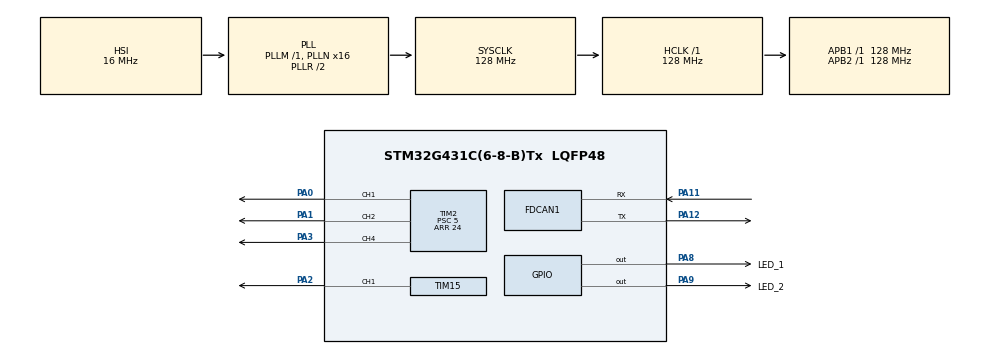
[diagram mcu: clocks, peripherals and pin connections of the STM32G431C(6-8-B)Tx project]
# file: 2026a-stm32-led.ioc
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Dma.Request0=TIM15_CH1
Dma.Request1=TIM2_CH4
Dma.Request2=TIM2_CH1
Dma.Request3=TIM2_CH2
Dma.TIM15_CH1.0.Direction=DMA_MEMORY_TO_PERIPH
Dma.TIM15_CH1.0.EventEnable=DISABLE
Dma.TIM15_CH1.0.Instance=DMA1_Channel1
Dma.TIM15_CH1.0.MemDataAlignment=DMA_MDATAALIGN_HALFWORD
Dma.TIM15_CH1.0.MemInc=DMA_MINC_ENABLE
Dma.TIM15_CH1.0.Mode=DMA_CIRCULAR
Dma.TIM15_CH1.0.PeriphDataAlignment=DMA_PDATAALIGN_HALFWORD
Dma.TIM15_CH1.0.PeriphInc=DMA_PINC_DISABLE
Dma.TIM15_CH1.0.Polarity=HAL_DMAMUX_REQ_GEN_RISING
Dma.TIM15_CH1.0.Priority=DMA_PRIORITY_MEDIUM
Dma.TIM15_CH1.0.RequestNumber=1
Dma.TIM15_CH1.0.SignalID=NONE
Dma.TIM15_CH1.0.SyncEnable=DISABLE
Dma.TIM15_CH1.0.SyncPolarity=HAL_DMAMUX_SYNC_NO_EVENT
Dma.TIM15_CH1.0.SyncRequestNumber=1
Dma.TIM15_CH1.0.SyncSignalID=NONE
Dma.TIM2_CH1.2.Direction=DMA_MEMORY_TO_PERIPH
Dma.TIM2_CH1.2.EventEnable=DISABLE
Dma.TIM2_CH1.2.Instance=DMA1_Channel3
Dma.TIM2_CH1.2.MemDataAlignment=DMA_MDATAALIGN_WORD
Dma.TIM2_CH1.2.MemInc=DMA_MINC_ENABLE
Dma.TIM2_CH1.2.Mode=DMA_CIRCULAR
Dma.TIM2_CH1.2.PeriphDataAlignment=DMA_PDATAALIGN_WORD
Dma.TIM2_CH1.2.PeriphInc=DMA_PINC_DISABLE
Dma.TIM2_CH1.2.Polarity=HAL_DMAMUX_REQ_GEN_RISING
Dma.TIM2_CH1.2.Priority=DMA_PRIORITY_LOW
Dma.TIM2_CH1.2.RequestNumber=1
Dma.TIM2_CH1.2.SignalID=NONE
Dma.TIM2_CH1.2.SyncEnable=DISABLE
Dma.TIM2_CH1.2.SyncPolarity=HAL_DMAMUX_SYNC_NO_EVENT
Dma.TIM2_CH1.2.SyncRequestNumber=1
Dma.TIM2_CH1.2.SyncSignalID=NONE
Dma.TIM2_CH2.3.Direction=DMA_MEMORY_TO_PERIPH
Dma.TIM2_CH2.3.EventEnable=DISABLE
Dma.TIM2_CH2.3.Instance=DMA1_Channel4
Dma.TIM2_CH2.3.MemDataAlignment=DMA_MDATAALIGN_WORD
Dma.TIM2_CH2.3.MemInc=DMA_MINC_ENABLE
Dma.TIM2_CH2.3.Mode=DMA_CIRCULAR
Dma.TIM2_CH2.3.PeriphDataAlignment=DMA_PDATAALIGN_WORD
Dma.TIM2_CH2.3.PeriphInc=DMA_PINC_DISABLE
Dma.TIM2_CH2.3.Polarity=HAL_DMAMUX_REQ_GEN_RISING
Dma.TIM2_CH2.3.Priority=DMA_PRIORITY_LOW
Dma.TIM2_CH2.3.RequestNumber=1
Dma.TIM2_CH2.3.SignalID=NONE
Dma.TIM2_CH2.3.SyncEnable=DISABLE
Dma.TIM2_CH2.3.SyncPolarity=HAL_DMAMUX_SYNC_NO_EVENT
Dma.TIM2_CH2.3.SyncRequestNumber=1
Dma.TIM2_CH2.3.SyncSignalID=NONE
Dma.TIM2_CH4.1.Direction=DMA_MEMORY_TO_PERIPH
Dma.TIM2_CH4.1.EventEnable=DISABLE
Dma.TIM2_CH4.1.Instance=DMA1_Channel2
Dma.TIM2_CH4.1.MemDataAlignment=DMA_MDATAALIGN_WORD
Dma.TIM2_CH4.1.MemInc=DMA_MINC_ENABLE
Dma.TIM2_CH4.1.Mode=DMA_CIRCULAR
Dma.TIM2_CH4.1.PeriphDataAlignment=DMA_PDATAALIGN_WORD
Dma.TIM2_CH4.1.PeriphInc=DMA_PINC_DISABLE
Dma.TIM2_CH4.1.Polarity=HAL_DMAMUX_REQ_GEN_RISING
Dma.TIM2_CH4.1.Priority=DMA_PRIORITY_LOW
Dma.TIM2_CH4.1.RequestNumber=1
Dma.TIM2_CH4.1.SignalID=NONE
Dma.TIM2_CH4.1.SyncEnable=DISABLE
Dma.TIM2_CH4.1.SyncPolarity=HAL_DMAMUX_SYNC_NO_EVENT
Dma.TIM2_CH4.1.SyncRequestNumber=1
Dma.TIM2_CH4.1.SyncSignalID=NONE
FDCAN1.CalculateBaudRateNominal=1000000
FDCAN1.CalculateTimeBitNominal=1000
FDCAN1.CalculateTimeQuantumNominal=62.5
FDCAN1.FrameFormat=FDCAN_FRAME_FD_NO_BRS
FDCAN1.NominalPrescaler=8
FDCAN1.NominalSyncJumpWidth=2
FDCAN1.NominalTimeSeg1=13
FDCAN1.NominalTimeSeg2=2
Mcu.Family=STM32G4
Mcu.Name=STM32G431C(6-8-B)Tx
Mcu.Package=LQFP48
NVIC.DMA1_Channel1_IRQn=true\:4\:0\:true\:false\:true\:false\:true\:true
NVIC.DMA1_Channel2_IRQn=true\:4\:0\:true\:false\:true\:false\:true\:true
NVIC.DMA1_Channel3_IRQn=true\:4\:0\:true\:false\:true\:false\:true\:true
NVIC.DMA1_Channel4_IRQn=true\:4\:0\:true\:false\:true\:false\:true\:true
NVIC.FDCAN1_IT0_IRQn=true\:7\:0\:true\:false\:true\:true\:true\:true
NVIC.PriorityGroup=NVIC_PRIORITYGROUP_4
NVIC.TIM1_BRK_TIM15_IRQn=true\:5\:0\:true\:false\:true\:true\:true\:true
NVIC.TIM2_IRQn=true\:6\:0\:true\:false\:true\:true\:true\:true
NVIC.TIM7_IRQn=true\:7\:0\:true\:false\:true\:true\:true\:true
PA0.Signal=S_TIM2_CH1
PA1.Signal=S_TIM2_CH2
PA11.Mode=FDCAN_Activate
PA11.Signal=FDCAN1_RX
PA12.Mode=FDCAN_Activate
PA12.Signal=FDCAN1_TX
PA13.Mode=Serial_Wire
PA13.Signal=SYS_JTMS-SWDIO
PA14.Mode=Serial_Wire
PA14.Signal=SYS_JTCK-SWCLK
PA2.Signal=S_TIM15_CH1
PA3.Signal=S_TIM2_CH4
PA8.GPIO_Label=LED_1
PA8.Signal=GPIO_Output
PA9.GPIO_Label=LED_2
PA9.Signal=GPIO_Output
ProjectManager.HeapSize=0x200
ProjectManager.StackSize=0x400
ProjectManager.TargetToolchain=CMake
RCC.ADC12Freq_Value=128000000
RCC.AHBFreq_Value=128000000
RCC.APB1Freq_Value=128000000
RCC.APB1TimFreq_Value=128000000
RCC.APB2Freq_Value=128000000
RCC.APB2TimFreq_Value=128000000
RCC.CortexFreq_Value=128000000
RCC.EXTERNAL_CLOCK_VALUE=12288000
RCC.HCLKFreq_Value=128000000
RCC.HSE_VALUE=8000000
RCC.HSI48_VALUE=48000000
RCC.HSI_VALUE=16000000
RCC.LSE_VALUE=32768
RCC.PLLN=16
RCC.SYSCLKFreq_VALUE=128000000
RCC.SYSCLKSource=RCC_SYSCLKSOURCE_PLLCLK
RCC.USBFreq_Value=128000000
RCC.VCOOutputFreq_Value=256000000
SH.S_TIM15_CH1.0=TIM15_CH1,PWM Generation1 CH1
SH.S_TIM2_CH1.0=TIM2_CH1,PWM Generation1 CH1
SH.S_TIM2_CH2.0=TIM2_CH2,PWM Generation2 CH2
SH.S_TIM2_CH4.0=TIM2_CH4,PWM Generation4 CH4
TIM15.AutoReloadPreload=TIM_AUTORELOAD_PRELOAD_ENABLE
TIM15.Channel-PWM\ Generation1\ CH1=TIM_CHANNEL_1
TIM15.OCIdleState_1=TIM_OCIDLESTATE_RESET
TIM15.PeriodNoDither=24
TIM15.Prescaler=5
TIM15.TIM_MasterOutputTrigger=TIM_TRGO_RESET
TIM2.AutoReloadPreload=TIM_AUTORELOAD_PRELOAD_ENABLE
TIM2.Channel-PWM\ Generation1\ CH1=TIM_CHANNEL_1
TIM2.Channel-PWM\ Generation2\ CH2=TIM_CHANNEL_2
TIM2.Channel-PWM\ Generation4\ CH4=TIM_CHANNEL_4
TIM2.PeriodNoDither=24
TIM2.Prescaler=5
TIM7.PeriodNoDither=9999
TIM7.Prescaler=127
VP_SYS_VS_DBSignals.Mode=DisableDeadBatterySignals
VP_TIM15_VS_ClockSourceINT.Mode=Internal
VP_TIM2_VS_ClockSourceINT.Mode=Internal
VP_TIM7_VS_ClockSourceINT.Mode=Enable_Timer
board=custom

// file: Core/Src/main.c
/* USER CODE BEGIN Header */
/**
 ******************************************************************************
 * @file           : main.c
 * @brief          : Main program body
 ******************************************************************************
 * @attention
 *
 * Copyright (c) 2026 STMicroelectronics.
 * All rights reserved.
 *
 * This software is licensed under terms that can be found in the LICENSE file
 * in the root directory of this software component.
 * If no LICENSE file comes with this software, it is provided AS-IS.
 *
 ******************************************************************************
 */
/* USER CODE END Header */
#include "main.h"
#include "dma.h"
#include "fdcan.h"
#include "tim.h"
#include "gpio.h"

/* USER CODE BEGIN Includes */
#include "app/app.hpp"
/* USER CODE END Includes */

void SystemClock_Config(void);

int main(void)
{

  /* MCU Configuration--------------------------------------------------------*/

  /* Reset of all peripherals, Initializes the Flash interface and the Systick. */
  HAL_Init();

  /* Configure the system clock */
  SystemClock_Config();

  /* Initialize all configured peripherals */
  MX_GPIO_Init();
  MX_DMA_Init();
  MX_FDCAN1_Init();
  MX_TIM2_Init();
  MX_TIM15_Init();
  MX_TIM7_Init();
  /* USER CODE BEGIN 2 */
    setup();
  /* USER CODE END 2 */

  /* Infinite loop */
    while (1) {

    /* USER CODE BEGIN 3 */
        loop();
    }
  /* USER CODE END 3 */
}

void SystemClock_Config(void)
{
  RCC_OscInitTypeDef RCC_OscInitStruct = {0};
  RCC_ClkInitTypeDef RCC_ClkInitStruct = {0};

  /** Configure the main internal regulator output voltage
  */
  HAL_PWREx_ControlVoltageScaling(PWR_REGULATOR_VOLTAGE_SCALE1);

  /** Initializes the RCC Oscillators according to the specified parameters
  * in the RCC_OscInitTypeDef structure.
  */
  RCC_OscInitStruct.OscillatorType = RCC_OSCILLATORTYPE_HSI;
  RCC_OscInitStruct.HSIState = RCC_HSI_ON;
  RCC_OscInitStruct.HSICalibrationValue = RCC_HSICALIBRATION_DEFAULT;
  RCC_OscInitStruct.PLL.PLLState = RCC_PLL_ON;
  RCC_OscInitStruct.PLL.PLLSource = RCC_PLLSOURCE_HSI;
  RCC_OscInitStruct.PLL.PLLM = RCC_PLLM_DIV1;
  RCC_OscInitStruct.PLL.PLLN = 16;
  RCC_OscInitStruct.PLL.PLLP = RCC_PLLP_DIV2;
  RCC_OscInitStruct.PLL.PLLQ = RCC_PLLQ_DIV2;
  RCC_OscInitStruct.PLL.PLLR = RCC_PLLR_DIV2;
  if (HAL_RCC_OscConfig(&RCC_OscInitStruct) != HAL_OK)
  {
    Error_Handler();
  }

  /** Initializes the CPU, AHB and APB buses clocks
  */
  RCC_ClkInitStruct.ClockType = RCC_CLOCKTYPE_HCLK|RCC_CLOCKTYPE_SYSCLK
                              |RCC_CLOCKTYPE_PCLK1|RCC_CLOCKTYPE_PCLK2;
  RCC_ClkInitStruct.SYSCLKSource = RCC_SYSCLKSOURCE_PLLCLK;
  RCC_ClkInitStruct.AHBCLKDivider = RCC_SYSCLK_DIV1;
  RCC_ClkInitStruct.APB1CLKDivider = RCC_HCLK_DIV1;
  RCC_ClkInitStruct.APB2CLKDivider = RCC_HCLK_DIV1;

  if (HAL_RCC_ClockConfig(&RCC_ClkInitStruct, FLASH_LATENCY_4) != HAL_OK)
  {
    Error_Handler();
  }
}

void Error_Handler(void)
{
    __disable_irq();
    while (1) {
    }
}
